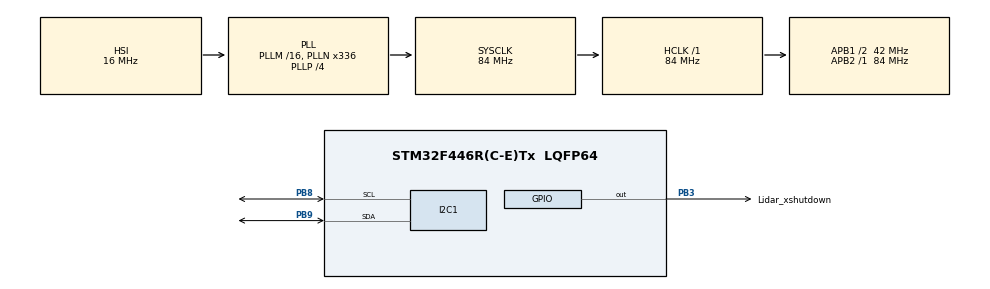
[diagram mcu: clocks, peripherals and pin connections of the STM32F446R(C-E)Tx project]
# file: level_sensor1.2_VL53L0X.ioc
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Mcu.Family=STM32F4
Mcu.Name=STM32F446R(C-E)Tx
Mcu.Package=LQFP64
NVIC.PriorityGroup=NVIC_PRIORITYGROUP_0
PB3.GPIO_Label=Lidar_xshutdown
PB3.Signal=GPIO_Output
PB8.Mode=I2C
PB8.Signal=I2C1_SCL
PB9.Mode=I2C
PB9.Signal=I2C1_SDA
PH0-OSC_IN.Mode=HSE-External-Oscillator
PH0-OSC_IN.Signal=RCC_OSC_IN
PH1-OSC_OUT.Mode=HSE-External-Oscillator
PH1-OSC_OUT.Signal=RCC_OSC_OUT
ProjectManager.HeapSize=0x200
ProjectManager.StackSize=0x400
ProjectManager.TargetToolchain=STM32CubeIDE
RCC.48MHZClocksFreq_Value=84000000
RCC.AHBFreq_Value=84000000
RCC.APB1CLKDivider=RCC_HCLK_DIV2
RCC.APB1Freq_Value=42000000
RCC.APB1TimFreq_Value=84000000
RCC.APB2Freq_Value=84000000
RCC.APB2TimFreq_Value=84000000
RCC.CortexFreq_Value=84000000
RCC.FLatency-AdvancedSettings=FLASH_LATENCY_2
RCC.HCLKFreq_Value=84000000
RCC.HSE_VALUE=8000000
RCC.HSI_VALUE=16000000
RCC.PLLN=336
RCC.PLLP=RCC_PLLP_DIV4
RCC.SYSCLKFreq_VALUE=84000000
RCC.SYSCLKSource=RCC_SYSCLKSOURCE_PLLCLK
RCC.USBFreq_Value=168000000
RCC.VCOOutputFreq_Value=336000000
board=NUCLEO-F446RE

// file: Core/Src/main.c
/* USER CODE BEGIN Header */
/**
 ******************************************************************************
 * @file           : main.c
 * @brief          : Main program body
 ******************************************************************************
 * @attention
 *
 * Copyright (c) 2025 STMicroelectronics.
 * All rights reserved.
 *
 * This software is licensed under terms that can be found in the LICENSE file
 * in the root directory of this software component.
 * If no LICENSE file comes with this software, it is provided AS-IS.
 *
 ******************************************************************************
 */
/* USER CODE END Header */
#include "main.h"

/* USER CODE BEGIN Includes */
#include "vl53l0x_api.h"
/* USER CODE END Includes */

I2C_HandleTypeDef hi2c1;

/* USER CODE BEGIN PV */
VL53L0X_RangingMeasurementData_t RangingData;
VL53L0X_Dev_t  vl53l0x_c;
VL53L0X_DEV Dev = &vl53l0x_c;
/* USER CODE END PV */

void SystemClock_Config(void);
static void MX_GPIO_Init(void);
static void MX_I2C1_Init(void);

/* USER CODE BEGIN 0 */
void LidarInit() {
	uint32_t refSpadCount;
	uint8_t isApertureSpads;
	uint8_t VhvSettings;
	uint8_t PhaseCal;
	VL53L0X_WaitDeviceBooted( Dev );
	VL53L0X_DataInit( Dev );
	VL53L0X_StaticInit( Dev );
	VL53L0X_PerformRefCalibration(Dev, &VhvSettings, &PhaseCal);
	VL53L0X_PerformRefSpadManagement(Dev, &refSpadCount, &isApertureSpads);
	VL53L0X_SetDeviceMode(Dev, VL53L0X_DEVICEMODE_SINGLE_RANGING);

	VL53L0X_SetLimitCheckEnable(Dev, VL53L0X_CHECKENABLE_SIGMA_FINAL_RANGE, 1);
	VL53L0X_SetLimitCheckEnable(Dev, VL53L0X_CHECKENABLE_SIGNAL_RATE_FINAL_RANGE, 1);
	VL53L0X_SetLimitCheckValue(Dev, VL53L0X_CHECKENABLE_SIGNAL_RATE_FINAL_RANGE, (FixPoint1616_t)(0.1*65536));
	VL53L0X_SetLimitCheckValue(Dev, VL53L0X_CHECKENABLE_SIGMA_FINAL_RANGE, (FixPoint1616_t)(60*65536));
	VL53L0X_SetMeasurementTimingBudgetMicroSeconds(Dev, 33000);
	VL53L0X_SetVcselPulsePeriod(Dev, VL53L0X_VCSEL_PERIOD_PRE_RANGE, 18);
	VL53L0X_SetVcselPulsePeriod(Dev, VL53L0X_VCSEL_PERIOD_FINAL_RANGE, 14);
}
float distanceIncms =0;
/* USER CODE END 0 */

int main(void)
{

	/* MCU Configuration--------------------------------------------------------*/

	/* Reset of all peripherals, Initializes the Flash interface and the Systick. */
	HAL_Init();

	/* Configure the system clock */
	SystemClock_Config();

	/* Initialize all configured peripherals */
	MX_GPIO_Init();
	MX_I2C1_Init();
	/* USER CODE BEGIN 2 */
	Dev->I2cHandle = &hi2c1;
	Dev->I2cDevAddr = 0x52;

	HAL_GPIO_WritePin(Lidar_xshutdown_GPIO_Port, Lidar_xshutdown_Pin, GPIO_PIN_RESET);
	HAL_Delay(20);
	HAL_GPIO_WritePin(Lidar_xshutdown_GPIO_Port, Lidar_xshutdown_Pin, GPIO_PIN_SET);
	HAL_Delay(20);
	LidarInit();
	VL53L0X_SetDeviceAddress(Dev, 0x62);

	/* USER CODE END 2 */

	/* Infinite loop */
	while (1)
	{

		/* USER CODE BEGIN 3 */
		Dev->I2cDevAddr = 0x62;
		VL53L0X_PerformSingleRangingMeasurement(Dev, &RangingData);
		distanceIncms = RangingData.RangeMilliMeter/10;
	}
	/* USER CODE END 3 */
}

void SystemClock_Config(void)
{
	RCC_OscInitTypeDef RCC_OscInitStruct = {0};
	RCC_ClkInitTypeDef RCC_ClkInitStruct = {0};

	/** Configure the main internal regulator output voltage
	 */
	__HAL_RCC_PWR_CLK_ENABLE();
	__HAL_PWR_VOLTAGESCALING_CONFIG(PWR_REGULATOR_VOLTAGE_SCALE3);

	/** Initializes the RCC Oscillators according to the specified parameters
	 * in the RCC_OscInitTypeDef structure.
	 */
	RCC_OscInitStruct.OscillatorType = RCC_OSCILLATORTYPE_HSI;
	RCC_OscInitStruct.HSIState = RCC_HSI_ON;
	RCC_OscInitStruct.HSICalibrationValue = RCC_HSICALIBRATION_DEFAULT;
	RCC_OscInitStruct.PLL.PLLState = RCC_PLL_ON;
	RCC_OscInitStruct.PLL.PLLSource = RCC_PLLSOURCE_HSI;
	RCC_OscInitStruct.PLL.PLLM = 16;
	RCC_OscInitStruct.PLL.PLLN = 336;
	RCC_OscInitStruct.PLL.PLLP = RCC_PLLP_DIV4;
	RCC_OscInitStruct.PLL.PLLQ = 2;
	RCC_OscInitStruct.PLL.PLLR = 2;
	if (HAL_RCC_OscConfig(&RCC_OscInitStruct) != HAL_OK)
	{
		Error_Handler();
	}

	/** Initializes the CPU, AHB and APB buses clocks
	 */
	RCC_ClkInitStruct.ClockType = RCC_CLOCKTYPE_HCLK|RCC_CLOCKTYPE_SYSCLK
			|RCC_CLOCKTYPE_PCLK1|RCC_CLOCKTYPE_PCLK2;
	RCC_ClkInitStruct.SYSCLKSource = RCC_SYSCLKSOURCE_PLLCLK;
	RCC_ClkInitStruct.AHBCLKDivider = RCC_SYSCLK_DIV1;
	RCC_ClkInitStruct.APB1CLKDivider = RCC_HCLK_DIV2;
	RCC_ClkInitStruct.APB2CLKDivider = RCC_HCLK_DIV1;

	if (HAL_RCC_ClockConfig(&RCC_ClkInitStruct, FLASH_LATENCY_2) != HAL_OK)
	{
		Error_Handler();
	}
}

static void MX_I2C1_Init(void)
{

	hi2c1.Instance = I2C1;
	hi2c1.Init.ClockSpeed = 100000;
	hi2c1.Init.DutyCycle = I2C_DUTYCYCLE_2;
	hi2c1.Init.OwnAddress1 = 0;
	hi2c1.Init.AddressingMode = I2C_ADDRESSINGMODE_7BIT;
	hi2c1.Init.DualAddressMode = I2C_DUALADDRESS_DISABLE;
	hi2c1.Init.OwnAddress2 = 0;
	hi2c1.Init.GeneralCallMode = I2C_GENERALCALL_DISABLE;
	hi2c1.Init.NoStretchMode = I2C_NOSTRETCH_DISABLE;
	if (HAL_I2C_Init(&hi2c1) != HAL_OK)
	{
		Error_Handler();
	}

}

static void MX_GPIO_Init(void)
{
	GPIO_InitTypeDef GPIO_InitStruct = {0};

	/* GPIO Ports Clock Enable */
	__HAL_RCC_GPIOH_CLK_ENABLE();
	__HAL_RCC_GPIOB_CLK_ENABLE();

	/*Configure GPIO pin Output Level */
	HAL_GPIO_WritePin(Lidar_xshutdown_GPIO_Port, Lidar_xshutdown_Pin, GPIO_PIN_RESET);

	/*Configure GPIO pin : Lidar_xshutdown_Pin */
	GPIO_InitStruct.Pin = Lidar_xshutdown_Pin;
	GPIO_InitStruct.Mode = GPIO_MODE_OUTPUT_PP;
	GPIO_InitStruct.Pull = GPIO_NOPULL;
	GPIO_InitStruct.Speed = GPIO_SPEED_FREQ_LOW;
	HAL_GPIO_Init(Lidar_xshutdown_GPIO_Port, &GPIO_InitStruct);

}

void Error_Handler(void)
{
	__disable_irq();
	while (1)
	{
	}
}
